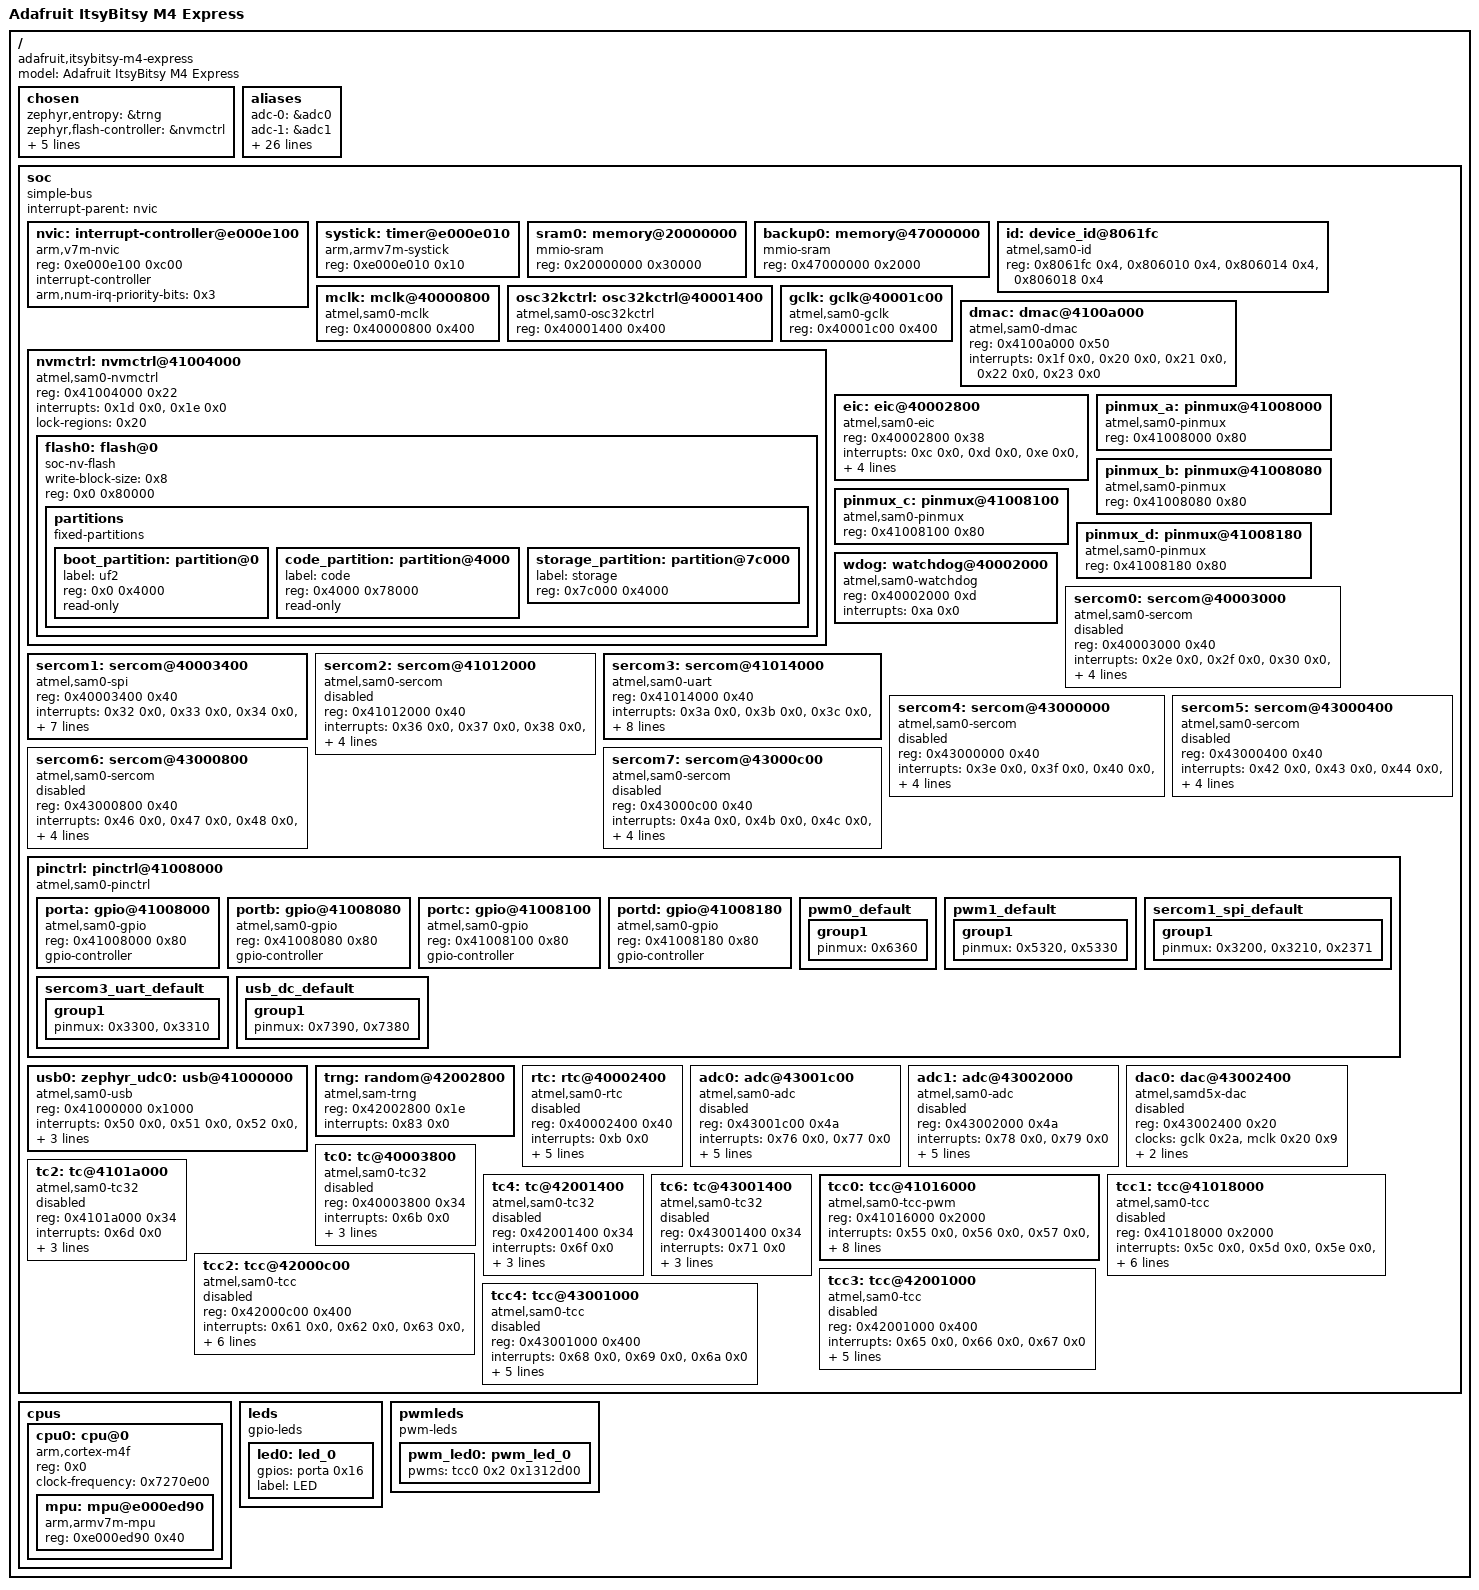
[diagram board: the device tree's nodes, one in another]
/dts-v1/;

/* node '/' defined in zephyr/dts/common/skeleton.dtsi:9 */
/ {
	#address-cells = < 0x1 >;                     /* in zephyr/dts/common/skeleton.dtsi:10 */
	#size-cells = < 0x1 >;                        /* in zephyr/dts/common/skeleton.dtsi:11 */
	model = "Adafruit ItsyBitsy M4 Express";      /* in zephyr/boards/adafruit/itsybitsy_m4_express/adafruit_itsybitsy_m4_express.dts:12 */
	compatible = "adafruit,itsybitsy-m4-express"; /* in zephyr/boards/adafruit/itsybitsy_m4_express/adafruit_itsybitsy_m4_express.dts:13 */

	/* node '/chosen' defined in zephyr/dts/common/skeleton.dtsi:13 */
	chosen {
		zephyr,entropy = &trng;                  /* in zephyr/dts/arm/atmel/samd5x.dtsi:51 */
		zephyr,flash-controller = &nvmctrl;      /* in zephyr/dts/arm/atmel/samd5x.dtsi:52 */
		zephyr,console = &sercom3;               /* in zephyr/boards/adafruit/itsybitsy_m4_express/adafruit_itsybitsy_m4_express.dts:16 */
		zephyr,shell-uart = &sercom3;            /* in zephyr/boards/adafruit/itsybitsy_m4_express/adafruit_itsybitsy_m4_express.dts:17 */
		zephyr,sram = &sram0;                    /* in zephyr/boards/adafruit/itsybitsy_m4_express/adafruit_itsybitsy_m4_express.dts:18 */
		zephyr,flash = &flash0;                  /* in zephyr/boards/adafruit/itsybitsy_m4_express/adafruit_itsybitsy_m4_express.dts:19 */
		zephyr,code-partition = &code_partition; /* in zephyr/boards/adafruit/itsybitsy_m4_express/adafruit_itsybitsy_m4_express.dts:20 */
	};

	/* node '/aliases' defined in zephyr/dts/common/skeleton.dtsi:15 */
	aliases {
		adc-0 = &adc0;        /* in zephyr/dts/arm/atmel/samd5x.dtsi:16 */
		adc-1 = &adc1;        /* in zephyr/dts/arm/atmel/samd5x.dtsi:17 */
		port-a = &porta;      /* in zephyr/dts/arm/atmel/samd5x.dtsi:19 */
		port-b = &portb;      /* in zephyr/dts/arm/atmel/samd5x.dtsi:20 */
		port-c = &portc;      /* in zephyr/dts/arm/atmel/samd5x.dtsi:21 */
		port-d = &portd;      /* in zephyr/dts/arm/atmel/samd5x.dtsi:22 */
		rtc = &rtc;           /* in zephyr/dts/arm/atmel/samd5x.dtsi:24 */
		sercom-0 = &sercom0;  /* in zephyr/dts/arm/atmel/samd5x.dtsi:26 */
		sercom-1 = &sercom1;  /* in zephyr/dts/arm/atmel/samd5x.dtsi:27 */
		sercom-2 = &sercom2;  /* in zephyr/dts/arm/atmel/samd5x.dtsi:28 */
		sercom-3 = &sercom3;  /* in zephyr/dts/arm/atmel/samd5x.dtsi:29 */
		sercom-4 = &sercom4;  /* in zephyr/dts/arm/atmel/samd5x.dtsi:30 */
		sercom-5 = &sercom5;  /* in zephyr/dts/arm/atmel/samd5x.dtsi:31 */
		sercom-6 = &sercom6;  /* in zephyr/dts/arm/atmel/samd5x.dtsi:32 */
		sercom-7 = &sercom7;  /* in zephyr/dts/arm/atmel/samd5x.dtsi:33 */
		tc-0 = &tc0;          /* in zephyr/dts/arm/atmel/samd5x.dtsi:35 */
		tc-2 = &tc2;          /* in zephyr/dts/arm/atmel/samd5x.dtsi:36 */
		tc-4 = &tc4;          /* in zephyr/dts/arm/atmel/samd5x.dtsi:37 */
		tc-6 = &tc6;          /* in zephyr/dts/arm/atmel/samd5x.dtsi:38 */
		tcc-0 = &tcc0;        /* in zephyr/dts/arm/atmel/samd5x.dtsi:40 */
		tcc-1 = &tcc1;        /* in zephyr/dts/arm/atmel/samd5x.dtsi:41 */
		tcc-2 = &tcc2;        /* in zephyr/dts/arm/atmel/samd5x.dtsi:42 */
		tcc-3 = &tcc3;        /* in zephyr/dts/arm/atmel/samd5x.dtsi:43 */
		tcc-4 = &tcc4;        /* in zephyr/dts/arm/atmel/samd5x.dtsi:44 */
		watchdog0 = &wdog;    /* in zephyr/dts/arm/atmel/samd5x.dtsi:46 */
		led0 = &led0;         /* in zephyr/boards/adafruit/itsybitsy_m4_express/adafruit_itsybitsy_m4_express.dts:25 */
		pwm-led0 = &pwm_led0; /* in zephyr/boards/adafruit/itsybitsy_m4_express/adafruit_itsybitsy_m4_express.dts:26 */
		pwm-0 = &tcc0;        /* in zephyr/boards/adafruit/itsybitsy_m4_express/adafruit_itsybitsy_m4_express.dts:27 */
	};

	/* node '/soc' defined in zephyr/dts/arm/armv7-m.dtsi:6 */
	soc {
		#address-cells = < 0x1 >;     /* in zephyr/dts/arm/armv7-m.dtsi:7 */
		#size-cells = < 0x1 >;        /* in zephyr/dts/arm/armv7-m.dtsi:8 */
		compatible = "simple-bus";    /* in zephyr/dts/arm/armv7-m.dtsi:9 */
		interrupt-parent = < &nvic >; /* in zephyr/dts/arm/armv7-m.dtsi:10 */
		ranges;                       /* in zephyr/dts/arm/armv7-m.dtsi:11 */

		/* node '/soc/interrupt-controller@e000e100' defined in zephyr/dts/arm/armv7-m.dtsi:13 */
		nvic: interrupt-controller@e000e100 {
			#address-cells = < 0x1 >;            /* in zephyr/dts/arm/armv7-m.dtsi:14 */
			compatible = "arm,v7m-nvic";         /* in zephyr/dts/arm/armv7-m.dtsi:15 */
			reg = < 0xe000e100 0xc00 >;          /* in zephyr/dts/arm/armv7-m.dtsi:16 */
			interrupt-controller;                /* in zephyr/dts/arm/armv7-m.dtsi:17 */
			#interrupt-cells = < 0x2 >;          /* in zephyr/dts/arm/armv7-m.dtsi:18 */
			arm,num-irq-priority-bits = < 0x3 >; /* in zephyr/dts/arm/atmel/samd5x.dtsi:522 */
			phandle = < 0x1 >;                   /* in zephyr/dts/arm/armv7-m.dtsi:10 */
		};

		/* node '/soc/timer@e000e010' defined in zephyr/dts/arm/armv7-m.dtsi:21 */
		systick: timer@e000e010 {
			compatible = "arm,armv7m-systick"; /* in zephyr/dts/arm/armv7-m.dtsi:22 */
			reg = < 0xe000e010 0x10 >;         /* in zephyr/dts/arm/armv7-m.dtsi:23 */
		};

		/* node '/soc/memory@20000000' defined in zephyr/dts/arm/atmel/samd5x.dtsi:76 */
		sram0: memory@20000000 {
			compatible = "mmio-sram";     /* in zephyr/dts/arm/atmel/samd5x.dtsi:77 */
			reg = < 0x20000000 0x30000 >; /* in zephyr/dts/arm/atmel/samd5xx19.dtsi:19 */
		};

		/* node '/soc/memory@47000000' defined in zephyr/dts/arm/atmel/samd5x.dtsi:81 */
		backup0: memory@47000000 {
			compatible = "mmio-sram";    /* in zephyr/dts/arm/atmel/samd5x.dtsi:82 */
			reg = < 0x47000000 0x2000 >; /* in zephyr/dts/arm/atmel/samd5x.dtsi:83 */
		};

		/* node '/soc/device_id@8061fc' defined in zephyr/dts/arm/atmel/samd5x.dtsi:86 */
		id: device_id@8061fc {
			compatible = "atmel,sam0-id"; /* in zephyr/dts/arm/atmel/samd5x.dtsi:87 */
			reg = < 0x8061fc 0x4 >,
			      < 0x806010 0x4 >,
			      < 0x806014 0x4 >,
			      < 0x806018 0x4 >;       /* in zephyr/dts/arm/atmel/samd5x.dtsi:88 */
		};

		/* node '/soc/mclk@40000800' defined in zephyr/dts/arm/atmel/samd5x.dtsi:94 */
		mclk: mclk@40000800 {
			compatible = "atmel,sam0-mclk"; /* in zephyr/dts/arm/atmel/samd5x.dtsi:95 */
			reg = < 0x40000800 0x400 >;     /* in zephyr/dts/arm/atmel/samd5x.dtsi:96 */
			#clock-cells = < 0x2 >;         /* in zephyr/dts/arm/atmel/samd5x.dtsi:98 */
			phandle = < 0x3 >;              /* in zephyr/dts/arm/atmel/samd5x.dtsi:181 */
		};

		/* node '/soc/osc32kctrl@40001400' defined in zephyr/dts/arm/atmel/samd5x.dtsi:101 */
		osc32kctrl: osc32kctrl@40001400 {
			compatible = "atmel,sam0-osc32kctrl";  /* in zephyr/dts/arm/atmel/samd5x.dtsi:102 */
			reg = < 0x40001400 0x400 >;            /* in zephyr/dts/arm/atmel/samd5x.dtsi:103 */
			#clock-cells = < 0x0 >;                /* in zephyr/dts/arm/atmel/samd5x.dtsi:104 */
			#atmel,assigned-clock-cells = < 0x1 >; /* in zephyr/dts/arm/atmel/samd5x.dtsi:105 */
			phandle = < 0x7 >;                     /* in zephyr/dts/arm/atmel/samd5x.dtsi:332 */
		};

		/* node '/soc/gclk@40001c00' defined in zephyr/dts/arm/atmel/samd5x.dtsi:108 */
		gclk: gclk@40001c00 {
			compatible = "atmel,sam0-gclk";        /* in zephyr/dts/arm/atmel/samd5x.dtsi:109 */
			reg = < 0x40001c00 0x400 >;            /* in zephyr/dts/arm/atmel/samd5x.dtsi:110 */
			#clock-cells = < 0x1 >;                /* in zephyr/dts/arm/atmel/samd5x.dtsi:112 */
			#atmel,assigned-clock-cells = < 0x1 >; /* in zephyr/dts/arm/atmel/samd5x.dtsi:113 */
			phandle = < 0x2 >;                     /* in zephyr/dts/arm/atmel/samd5x.dtsi:181 */
		};

		/* node '/soc/nvmctrl@41004000' defined in zephyr/dts/arm/atmel/samd5x.dtsi:116 */
		nvmctrl: nvmctrl@41004000 {
			compatible = "atmel,sam0-nvmctrl"; /* in zephyr/dts/arm/atmel/samd5x.dtsi:117 */
			reg = < 0x41004000 0x22 >;         /* in zephyr/dts/arm/atmel/samd5x.dtsi:118 */
			interrupts = < 0x1d 0x0 >,
			             < 0x1e 0x0 >;         /* in zephyr/dts/arm/atmel/samd5x.dtsi:119 */
			#address-cells = < 0x1 >;          /* in zephyr/dts/arm/atmel/samd5x.dtsi:121 */
			#size-cells = < 0x1 >;             /* in zephyr/dts/arm/atmel/samd5x.dtsi:122 */
			lock-regions = < 0x20 >;           /* in zephyr/dts/arm/atmel/samd5x.dtsi:124 */

			/* node '/soc/nvmctrl@41004000/flash@0' defined in zephyr/dts/arm/atmel/samd5x.dtsi:126 */
			flash0: flash@0 {
				compatible = "soc-nv-flash"; /* in zephyr/dts/arm/atmel/samd5x.dtsi:127 */
				write-block-size = < 0x8 >;  /* in zephyr/dts/arm/atmel/samd5x.dtsi:129 */
				reg = < 0x0 0x80000 >;       /* in zephyr/dts/arm/atmel/samd5xx19.dtsi:14 */

				/* node '/soc/nvmctrl@41004000/flash@0/partitions' defined in zephyr/boards/adafruit/itsybitsy_m4_express/adafruit_itsybitsy_m4_express.dts:98 */
				partitions {
					compatible = "fixed-partitions"; /* in zephyr/boards/adafruit/itsybitsy_m4_express/adafruit_itsybitsy_m4_express.dts:99 */
					#address-cells = < 0x1 >;        /* in zephyr/boards/adafruit/itsybitsy_m4_express/adafruit_itsybitsy_m4_express.dts:100 */
					#size-cells = < 0x1 >;           /* in zephyr/boards/adafruit/itsybitsy_m4_express/adafruit_itsybitsy_m4_express.dts:101 */

					/* node '/soc/nvmctrl@41004000/flash@0/partitions/partition@0' defined in zephyr/boards/adafruit/itsybitsy_m4_express/adafruit_itsybitsy_m4_express.dts:103 */
					boot_partition: partition@0 {
						label = "uf2";        /* in zephyr/boards/adafruit/itsybitsy_m4_express/adafruit_itsybitsy_m4_express.dts:104 */
						reg = < 0x0 0x4000 >; /* in zephyr/boards/adafruit/itsybitsy_m4_express/adafruit_itsybitsy_m4_express.dts:105 */
						read-only;            /* in zephyr/boards/adafruit/itsybitsy_m4_express/adafruit_itsybitsy_m4_express.dts:106 */
					};

					/* node '/soc/nvmctrl@41004000/flash@0/partitions/partition@4000' defined in zephyr/boards/adafruit/itsybitsy_m4_express/adafruit_itsybitsy_m4_express.dts:109 */
					code_partition: partition@4000 {
						label = "code";           /* in zephyr/boards/adafruit/itsybitsy_m4_express/adafruit_itsybitsy_m4_express.dts:110 */
						reg = < 0x4000 0x78000 >; /* in zephyr/boards/adafruit/itsybitsy_m4_express/adafruit_itsybitsy_m4_express.dts:111 */
						read-only;                /* in zephyr/boards/adafruit/itsybitsy_m4_express/adafruit_itsybitsy_m4_express.dts:112 */
					};

					/* node '/soc/nvmctrl@41004000/flash@0/partitions/partition@7c000' defined in zephyr/boards/adafruit/itsybitsy_m4_express/adafruit_itsybitsy_m4_express.dts:120 */
					storage_partition: partition@7c000 {
						label = "storage";        /* in zephyr/boards/adafruit/itsybitsy_m4_express/adafruit_itsybitsy_m4_express.dts:121 */
						reg = < 0x7c000 0x4000 >; /* in zephyr/boards/adafruit/itsybitsy_m4_express/adafruit_itsybitsy_m4_express.dts:122 */
					};
				};
			};
		};

		/* node '/soc/dmac@4100a000' defined in zephyr/dts/arm/atmel/samd5x.dtsi:133 */
		dmac: dmac@4100a000 {
			compatible = "atmel,sam0-dmac"; /* in zephyr/dts/arm/atmel/samd5x.dtsi:134 */
			reg = < 0x4100a000 0x50 >;      /* in zephyr/dts/arm/atmel/samd5x.dtsi:135 */
			interrupts = < 0x1f 0x0 >,
			             < 0x20 0x0 >,
			             < 0x21 0x0 >,
			             < 0x22 0x0 >,
			             < 0x23 0x0 >;      /* in zephyr/dts/arm/atmel/samd5x.dtsi:136 */
			#dma-cells = < 0x2 >;           /* in zephyr/dts/arm/atmel/samd5x.dtsi:139 */
			status = "okay";                /* in zephyr/boards/adafruit/itsybitsy_m4_express/adafruit_itsybitsy_m4_express.dts:94 */
		};

		/* node '/soc/eic@40002800' defined in zephyr/dts/arm/atmel/samd5x.dtsi:142 */
		eic: eic@40002800 {
			compatible = "atmel,sam0-eic"; /* in zephyr/dts/arm/atmel/samd5x.dtsi:143 */
			reg = < 0x40002800 0x38 >;     /* in zephyr/dts/arm/atmel/samd5x.dtsi:144 */
			interrupts = < 0xc 0x0 >,
			             < 0xd 0x0 >,
			             < 0xe 0x0 >,
			             < 0xf 0x0 >,
			             < 0x10 0x0 >,
			             < 0x11 0x0 >,
			             < 0x12 0x0 >,
			             < 0x13 0x0 >,
			             < 0x14 0x0 >,
			             < 0x15 0x0 >,
			             < 0x16 0x0 >,
			             < 0x17 0x0 >,
			             < 0x18 0x0 >,
			             < 0x19 0x0 >,
			             < 0x1a 0x0 >,
			             < 0x1b 0x0 >;     /* in zephyr/dts/arm/atmel/samd5x.dtsi:145 */
		};

		/* node '/soc/pinmux@41008000' defined in zephyr/dts/arm/atmel/samd5x.dtsi:151 */
		pinmux_a: pinmux@41008000 {
			compatible = "atmel,sam0-pinmux"; /* in zephyr/dts/arm/atmel/samd5x.dtsi:152 */
			reg = < 0x41008000 0x80 >;        /* in zephyr/dts/arm/atmel/samd5x.dtsi:153 */
		};

		/* node '/soc/pinmux@41008080' defined in zephyr/dts/arm/atmel/samd5x.dtsi:156 */
		pinmux_b: pinmux@41008080 {
			compatible = "atmel,sam0-pinmux"; /* in zephyr/dts/arm/atmel/samd5x.dtsi:157 */
			reg = < 0x41008080 0x80 >;        /* in zephyr/dts/arm/atmel/samd5x.dtsi:158 */
		};

		/* node '/soc/pinmux@41008100' defined in zephyr/dts/arm/atmel/samd5x.dtsi:161 */
		pinmux_c: pinmux@41008100 {
			compatible = "atmel,sam0-pinmux"; /* in zephyr/dts/arm/atmel/samd5x.dtsi:162 */
			reg = < 0x41008100 0x80 >;        /* in zephyr/dts/arm/atmel/samd5x.dtsi:163 */
		};

		/* node '/soc/pinmux@41008180' defined in zephyr/dts/arm/atmel/samd5x.dtsi:166 */
		pinmux_d: pinmux@41008180 {
			compatible = "atmel,sam0-pinmux"; /* in zephyr/dts/arm/atmel/samd5x.dtsi:167 */
			reg = < 0x41008180 0x80 >;        /* in zephyr/dts/arm/atmel/samd5x.dtsi:168 */
		};

		/* node '/soc/watchdog@40002000' defined in zephyr/dts/arm/atmel/samd5x.dtsi:171 */
		wdog: watchdog@40002000 {
			compatible = "atmel,sam0-watchdog"; /* in zephyr/dts/arm/atmel/samd5x.dtsi:172 */
			reg = < 0x40002000 0xd >;           /* in zephyr/dts/arm/atmel/samd5x.dtsi:173 */
			interrupts = < 0xa 0x0 >;           /* in zephyr/dts/arm/atmel/samd5x.dtsi:174 */
		};

		/* node '/soc/sercom@40003000' defined in zephyr/dts/arm/atmel/samd5x.dtsi:177 */
		sercom0: sercom@40003000 {
			compatible = "atmel,sam0-sercom";      /* in zephyr/dts/arm/atmel/samd5x.dtsi:178 */
			reg = < 0x40003000 0x40 >;             /* in zephyr/dts/arm/atmel/samd5x.dtsi:179 */
			interrupts = < 0x2e 0x0 >,
			             < 0x2f 0x0 >,
			             < 0x30 0x0 >,
			             < 0x31 0x0 >;             /* in zephyr/dts/arm/atmel/samd5x.dtsi:180 */
			clocks = < &gclk 0x7 >,
			         < &mclk 0x14 0xc >;           /* in zephyr/dts/arm/atmel/samd5x.dtsi:181 */
			clock-names = "GCLK",
			              "MCLK";                  /* in zephyr/dts/arm/atmel/samd5x.dtsi:182 */
			atmel,assigned-clocks = < &gclk 0x0 >; /* in zephyr/dts/arm/atmel/samd5x.dtsi:183 */
			atmel,assigned-clock-names = "GCLK";   /* in zephyr/dts/arm/atmel/samd5x.dtsi:184 */
			status = "disabled";                   /* in zephyr/dts/arm/atmel/samd5x.dtsi:185 */
		};

		/* node '/soc/sercom@40003400' defined in zephyr/dts/arm/atmel/samd5x.dtsi:188 */
		sercom1: sercom@40003400 {
			reg = < 0x40003400 0x40 >;             /* in zephyr/dts/arm/atmel/samd5x.dtsi:190 */
			interrupts = < 0x32 0x0 >,
			             < 0x33 0x0 >,
			             < 0x34 0x0 >,
			             < 0x35 0x0 >;             /* in zephyr/dts/arm/atmel/samd5x.dtsi:191 */
			clocks = < &gclk 0x8 >,
			         < &mclk 0x14 0xd >;           /* in zephyr/dts/arm/atmel/samd5x.dtsi:192 */
			clock-names = "GCLK",
			              "MCLK";                  /* in zephyr/dts/arm/atmel/samd5x.dtsi:193 */
			atmel,assigned-clocks = < &gclk 0x0 >; /* in zephyr/dts/arm/atmel/samd5x.dtsi:194 */
			atmel,assigned-clock-names = "GCLK";   /* in zephyr/dts/arm/atmel/samd5x.dtsi:195 */
			status = "okay";                       /* in zephyr/boards/adafruit/itsybitsy_m4_express/adafruit_itsybitsy_m4_express.dts:64 */
			compatible = "atmel,sam0-spi";         /* in zephyr/boards/adafruit/itsybitsy_m4_express/adafruit_itsybitsy_m4_express.dts:65 */
			dipo = < 0x3 >;                        /* in zephyr/boards/adafruit/itsybitsy_m4_express/adafruit_itsybitsy_m4_express.dts:66 */
			dopo = < 0x0 >;                        /* in zephyr/boards/adafruit/itsybitsy_m4_express/adafruit_itsybitsy_m4_express.dts:67 */
			#address-cells = < 0x1 >;              /* in zephyr/boards/adafruit/itsybitsy_m4_express/adafruit_itsybitsy_m4_express.dts:69 */
			#size-cells = < 0x0 >;                 /* in zephyr/boards/adafruit/itsybitsy_m4_express/adafruit_itsybitsy_m4_express.dts:70 */
			pinctrl-0 = < &sercom1_spi_default >;  /* in zephyr/boards/adafruit/itsybitsy_m4_express/adafruit_itsybitsy_m4_express.dts:72 */
			pinctrl-names = "default";             /* in zephyr/boards/adafruit/itsybitsy_m4_express/adafruit_itsybitsy_m4_express.dts:73 */
		};

		/* node '/soc/sercom@41012000' defined in zephyr/dts/arm/atmel/samd5x.dtsi:199 */
		sercom2: sercom@41012000 {
			compatible = "atmel,sam0-sercom";      /* in zephyr/dts/arm/atmel/samd5x.dtsi:200 */
			reg = < 0x41012000 0x40 >;             /* in zephyr/dts/arm/atmel/samd5x.dtsi:201 */
			interrupts = < 0x36 0x0 >,
			             < 0x37 0x0 >,
			             < 0x38 0x0 >,
			             < 0x39 0x0 >;             /* in zephyr/dts/arm/atmel/samd5x.dtsi:202 */
			clocks = < &gclk 0x17 >,
			         < &mclk 0x18 0x9 >;           /* in zephyr/dts/arm/atmel/samd5x.dtsi:203 */
			clock-names = "GCLK",
			              "MCLK";                  /* in zephyr/dts/arm/atmel/samd5x.dtsi:204 */
			atmel,assigned-clocks = < &gclk 0x0 >; /* in zephyr/dts/arm/atmel/samd5x.dtsi:205 */
			atmel,assigned-clock-names = "GCLK";   /* in zephyr/dts/arm/atmel/samd5x.dtsi:206 */
			status = "disabled";                   /* in zephyr/dts/arm/atmel/samd5x.dtsi:207 */
		};

		/* node '/soc/sercom@41014000' defined in zephyr/dts/arm/atmel/samd5x.dtsi:210 */
		sercom3: sercom@41014000 {
			reg = < 0x41014000 0x40 >;             /* in zephyr/dts/arm/atmel/samd5x.dtsi:212 */
			interrupts = < 0x3a 0x0 >,
			             < 0x3b 0x0 >,
			             < 0x3c 0x0 >,
			             < 0x3d 0x0 >;             /* in zephyr/dts/arm/atmel/samd5x.dtsi:213 */
			clocks = < &gclk 0x18 >,
			         < &mclk 0x18 0xa >;           /* in zephyr/dts/arm/atmel/samd5x.dtsi:214 */
			clock-names = "GCLK",
			              "MCLK";                  /* in zephyr/dts/arm/atmel/samd5x.dtsi:215 */
			atmel,assigned-clocks = < &gclk 0x0 >; /* in zephyr/dts/arm/atmel/samd5x.dtsi:216 */
			atmel,assigned-clock-names = "GCLK";   /* in zephyr/dts/arm/atmel/samd5x.dtsi:217 */
			status = "okay";                       /* in zephyr/boards/adafruit/itsybitsy_m4_express/adafruit_itsybitsy_m4_express.dts:53 */
			compatible = "atmel,sam0-uart";        /* in zephyr/boards/adafruit/itsybitsy_m4_express/adafruit_itsybitsy_m4_express.dts:54 */
			current-speed = < 0x1c200 >;           /* in zephyr/boards/adafruit/itsybitsy_m4_express/adafruit_itsybitsy_m4_express.dts:55 */
			rxpo = < 0x1 >;                        /* in zephyr/boards/adafruit/itsybitsy_m4_express/adafruit_itsybitsy_m4_express.dts:56 */
			txpo = < 0x0 >;                        /* in zephyr/boards/adafruit/itsybitsy_m4_express/adafruit_itsybitsy_m4_express.dts:57 */
			pinctrl-0 = < &sercom3_uart_default >; /* in zephyr/boards/adafruit/itsybitsy_m4_express/adafruit_itsybitsy_m4_express.dts:59 */
			pinctrl-names = "default";             /* in zephyr/boards/adafruit/itsybitsy_m4_express/adafruit_itsybitsy_m4_express.dts:60 */
		};

		/* node '/soc/sercom@43000000' defined in zephyr/dts/arm/atmel/samd5x.dtsi:221 */
		sercom4: sercom@43000000 {
			compatible = "atmel,sam0-sercom";      /* in zephyr/dts/arm/atmel/samd5x.dtsi:222 */
			reg = < 0x43000000 0x40 >;             /* in zephyr/dts/arm/atmel/samd5x.dtsi:223 */
			interrupts = < 0x3e 0x0 >,
			             < 0x3f 0x0 >,
			             < 0x40 0x0 >,
			             < 0x41 0x0 >;             /* in zephyr/dts/arm/atmel/samd5x.dtsi:224 */
			clocks = < &gclk 0x22 >,
			         < &mclk 0x20 0x0 >;           /* in zephyr/dts/arm/atmel/samd5x.dtsi:225 */
			clock-names = "GCLK",
			              "MCLK";                  /* in zephyr/dts/arm/atmel/samd5x.dtsi:226 */
			atmel,assigned-clocks = < &gclk 0x0 >; /* in zephyr/dts/arm/atmel/samd5x.dtsi:227 */
			atmel,assigned-clock-names = "GCLK";   /* in zephyr/dts/arm/atmel/samd5x.dtsi:228 */
			status = "disabled";                   /* in zephyr/dts/arm/atmel/samd5x.dtsi:229 */
		};

		/* node '/soc/sercom@43000400' defined in zephyr/dts/arm/atmel/samd5x.dtsi:232 */
		sercom5: sercom@43000400 {
			compatible = "atmel,sam0-sercom";      /* in zephyr/dts/arm/atmel/samd5x.dtsi:233 */
			reg = < 0x43000400 0x40 >;             /* in zephyr/dts/arm/atmel/samd5x.dtsi:234 */
			interrupts = < 0x42 0x0 >,
			             < 0x43 0x0 >,
			             < 0x44 0x0 >,
			             < 0x45 0x0 >;             /* in zephyr/dts/arm/atmel/samd5x.dtsi:235 */
			clocks = < &gclk 0x23 >,
			         < &mclk 0x20 0x1 >;           /* in zephyr/dts/arm/atmel/samd5x.dtsi:236 */
			clock-names = "GCLK",
			              "MCLK";                  /* in zephyr/dts/arm/atmel/samd5x.dtsi:237 */
			atmel,assigned-clocks = < &gclk 0x0 >; /* in zephyr/dts/arm/atmel/samd5x.dtsi:238 */
			atmel,assigned-clock-names = "GCLK";   /* in zephyr/dts/arm/atmel/samd5x.dtsi:239 */
			status = "disabled";                   /* in zephyr/dts/arm/atmel/samd5x.dtsi:240 */
		};

		/* node '/soc/sercom@43000800' defined in zephyr/dts/arm/atmel/samd5x.dtsi:243 */
		sercom6: sercom@43000800 {
			compatible = "atmel,sam0-sercom";      /* in zephyr/dts/arm/atmel/samd5x.dtsi:244 */
			reg = < 0x43000800 0x40 >;             /* in zephyr/dts/arm/atmel/samd5x.dtsi:245 */
			interrupts = < 0x46 0x0 >,
			             < 0x47 0x0 >,
			             < 0x48 0x0 >,
			             < 0x49 0x0 >;             /* in zephyr/dts/arm/atmel/samd5x.dtsi:246 */
			clocks = < &gclk 0x24 >,
			         < &mclk 0x20 0x2 >;           /* in zephyr/dts/arm/atmel/samd5x.dtsi:247 */
			clock-names = "GCLK",
			              "MCLK";                  /* in zephyr/dts/arm/atmel/samd5x.dtsi:248 */
			atmel,assigned-clocks = < &gclk 0x0 >; /* in zephyr/dts/arm/atmel/samd5x.dtsi:249 */
			atmel,assigned-clock-names = "GCLK";   /* in zephyr/dts/arm/atmel/samd5x.dtsi:250 */
			status = "disabled";                   /* in zephyr/dts/arm/atmel/samd5x.dtsi:251 */
		};

		/* node '/soc/sercom@43000c00' defined in zephyr/dts/arm/atmel/samd5x.dtsi:254 */
		sercom7: sercom@43000c00 {
			compatible = "atmel,sam0-sercom";      /* in zephyr/dts/arm/atmel/samd5x.dtsi:255 */
			reg = < 0x43000c00 0x40 >;             /* in zephyr/dts/arm/atmel/samd5x.dtsi:256 */
			interrupts = < 0x4a 0x0 >,
			             < 0x4b 0x0 >,
			             < 0x4c 0x0 >,
			             < 0x4d 0x0 >;             /* in zephyr/dts/arm/atmel/samd5x.dtsi:257 */
			clocks = < &gclk 0x25 >,
			         < &mclk 0x20 0x3 >;           /* in zephyr/dts/arm/atmel/samd5x.dtsi:258 */
			clock-names = "GCLK",
			              "MCLK";                  /* in zephyr/dts/arm/atmel/samd5x.dtsi:259 */
			atmel,assigned-clocks = < &gclk 0x0 >; /* in zephyr/dts/arm/atmel/samd5x.dtsi:260 */
			atmel,assigned-clock-names = "GCLK";   /* in zephyr/dts/arm/atmel/samd5x.dtsi:261 */
			status = "disabled";                   /* in zephyr/dts/arm/atmel/samd5x.dtsi:262 */
		};

		/* node '/soc/pinctrl@41008000' defined in zephyr/dts/arm/atmel/samd5x.dtsi:265 */
		pinctrl: pinctrl@41008000 {
			compatible = "atmel,sam0-pinctrl";        /* in zephyr/dts/arm/atmel/samd5x.dtsi:266 */
			ranges = < 0x41008000 0x41008000 0x200 >; /* in zephyr/dts/arm/atmel/samd5x.dtsi:267 */
			#address-cells = < 0x1 >;                 /* in zephyr/dts/arm/atmel/samd5x.dtsi:269 */
			#size-cells = < 0x1 >;                    /* in zephyr/dts/arm/atmel/samd5x.dtsi:270 */

			/* node '/soc/pinctrl@41008000/gpio@41008000' defined in zephyr/dts/arm/atmel/samd5x.dtsi:272 */
			porta: gpio@41008000 {
				compatible = "atmel,sam0-gpio"; /* in zephyr/dts/arm/atmel/samd5x.dtsi:273 */
				reg = < 0x41008000 0x80 >;      /* in zephyr/dts/arm/atmel/samd5x.dtsi:274 */
				#atmel,pin-cells = < 0x2 >;     /* in zephyr/dts/arm/atmel/samd5x.dtsi:276 */
				#gpio-cells = < 0x2 >;          /* in zephyr/dts/arm/atmel/samd5x.dtsi:277 */
				gpio-controller;                /* in zephyr/dts/arm/atmel/samd5x.dtsi:279 */
				phandle = < 0x9 >;              /* in zephyr/boards/adafruit/itsybitsy_m4_express/adafruit_itsybitsy_m4_express.dts:34 */
			};

			/* node '/soc/pinctrl@41008000/gpio@41008080' defined in zephyr/dts/arm/atmel/samd5x.dtsi:282 */
			portb: gpio@41008080 {
				compatible = "atmel,sam0-gpio"; /* in zephyr/dts/arm/atmel/samd5x.dtsi:283 */
				reg = < 0x41008080 0x80 >;      /* in zephyr/dts/arm/atmel/samd5x.dtsi:284 */
				#atmel,pin-cells = < 0x2 >;     /* in zephyr/dts/arm/atmel/samd5x.dtsi:286 */
				#gpio-cells = < 0x2 >;          /* in zephyr/dts/arm/atmel/samd5x.dtsi:287 */
				gpio-controller;                /* in zephyr/dts/arm/atmel/samd5x.dtsi:289 */
			};

			/* node '/soc/pinctrl@41008000/gpio@41008100' defined in zephyr/dts/arm/atmel/samd5x.dtsi:292 */
			portc: gpio@41008100 {
				compatible = "atmel,sam0-gpio"; /* in zephyr/dts/arm/atmel/samd5x.dtsi:293 */
				reg = < 0x41008100 0x80 >;      /* in zephyr/dts/arm/atmel/samd5x.dtsi:294 */
				#atmel,pin-cells = < 0x2 >;     /* in zephyr/dts/arm/atmel/samd5x.dtsi:296 */
				#gpio-cells = < 0x2 >;          /* in zephyr/dts/arm/atmel/samd5x.dtsi:297 */
				gpio-controller;                /* in zephyr/dts/arm/atmel/samd5x.dtsi:299 */
			};

			/* node '/soc/pinctrl@41008000/gpio@41008180' defined in zephyr/dts/arm/atmel/samd5x.dtsi:302 */
			portd: gpio@41008180 {
				compatible = "atmel,sam0-gpio"; /* in zephyr/dts/arm/atmel/samd5x.dtsi:303 */
				reg = < 0x41008180 0x80 >;      /* in zephyr/dts/arm/atmel/samd5x.dtsi:304 */
				#atmel,pin-cells = < 0x2 >;     /* in zephyr/dts/arm/atmel/samd5x.dtsi:306 */
				#gpio-cells = < 0x2 >;          /* in zephyr/dts/arm/atmel/samd5x.dtsi:307 */
				gpio-controller;                /* in zephyr/dts/arm/atmel/samd5x.dtsi:309 */
			};

			/* node '/soc/pinctrl@41008000/pwm0_default' defined in zephyr/boards/adafruit/itsybitsy_m4_express/adafruit_itsybitsy_m4_express-pinctrl.dtsi:9 */
			pwm0_default: pwm0_default {
				phandle = < 0x8 >; /* in zephyr/boards/adafruit/itsybitsy_m4_express/adafruit_itsybitsy_m4_express.dts:82 */

				/* node '/soc/pinctrl@41008000/pwm0_default/group1' defined in zephyr/boards/adafruit/itsybitsy_m4_express/adafruit_itsybitsy_m4_express-pinctrl.dtsi:10 */
				group1 {
					pinmux = < 0x6360 >; /* in zephyr/boards/adafruit/itsybitsy_m4_express/adafruit_itsybitsy_m4_express-pinctrl.dtsi:11 */
				};
			};

			/* node '/soc/pinctrl@41008000/pwm1_default' defined in zephyr/boards/adafruit/itsybitsy_m4_express/adafruit_itsybitsy_m4_express-pinctrl.dtsi:15 */
			pwm1_default: pwm1_default {

				/* node '/soc/pinctrl@41008000/pwm1_default/group1' defined in zephyr/boards/adafruit/itsybitsy_m4_express/adafruit_itsybitsy_m4_express-pinctrl.dtsi:16 */
				group1 {
					pinmux = < 0x5320 >,
					         < 0x5330 >; /* in zephyr/boards/adafruit/itsybitsy_m4_express/adafruit_itsybitsy_m4_express-pinctrl.dtsi:17 */
				};
			};

			/* node '/soc/pinctrl@41008000/sercom1_spi_default' defined in zephyr/boards/adafruit/itsybitsy_m4_express/adafruit_itsybitsy_m4_express-pinctrl.dtsi:22 */
			sercom1_spi_default: sercom1_spi_default {
				phandle = < 0x4 >; /* in zephyr/boards/adafruit/itsybitsy_m4_express/adafruit_itsybitsy_m4_express.dts:72 */

				/* node '/soc/pinctrl@41008000/sercom1_spi_default/group1' defined in zephyr/boards/adafruit/itsybitsy_m4_express/adafruit_itsybitsy_m4_express-pinctrl.dtsi:23 */
				group1 {
					pinmux = < 0x3200 >,
					         < 0x3210 >,
					         < 0x2371 >; /* in zephyr/boards/adafruit/itsybitsy_m4_express/adafruit_itsybitsy_m4_express-pinctrl.dtsi:24 */
				};
			};

			/* node '/soc/pinctrl@41008000/sercom3_uart_default' defined in zephyr/boards/adafruit/itsybitsy_m4_express/adafruit_itsybitsy_m4_express-pinctrl.dtsi:30 */
			sercom3_uart_default: sercom3_uart_default {
				phandle = < 0x5 >; /* in zephyr/boards/adafruit/itsybitsy_m4_express/adafruit_itsybitsy_m4_express.dts:59 */

				/* node '/soc/pinctrl@41008000/sercom3_uart_default/group1' defined in zephyr/boards/adafruit/itsybitsy_m4_express/adafruit_itsybitsy_m4_express-pinctrl.dtsi:31 */
				group1 {
					pinmux = < 0x3300 >,
					         < 0x3310 >; /* in zephyr/boards/adafruit/itsybitsy_m4_express/adafruit_itsybitsy_m4_express-pinctrl.dtsi:32 */
				};
			};

			/* node '/soc/pinctrl@41008000/usb_dc_default' defined in zephyr/boards/adafruit/itsybitsy_m4_express/adafruit_itsybitsy_m4_express-pinctrl.dtsi:37 */
			usb_dc_default: usb_dc_default {
				phandle = < 0x6 >; /* in zephyr/boards/adafruit/itsybitsy_m4_express/adafruit_itsybitsy_m4_express.dts:89 */

				/* node '/soc/pinctrl@41008000/usb_dc_default/group1' defined in zephyr/boards/adafruit/itsybitsy_m4_express/adafruit_itsybitsy_m4_express-pinctrl.dtsi:38 */
				group1 {
					pinmux = < 0x7390 >,
					         < 0x7380 >; /* in zephyr/boards/adafruit/itsybitsy_m4_express/adafruit_itsybitsy_m4_express-pinctrl.dtsi:39 */
				};
			};
		};

		/* node '/soc/usb@41000000' defined in zephyr/dts/arm/atmel/samd5x.dtsi:313 */
		usb0: zephyr_udc0: usb@41000000 {
			compatible = "atmel,sam0-usb";   /* in zephyr/dts/arm/atmel/samd5x.dtsi:314 */
			reg = < 0x41000000 0x1000 >;     /* in zephyr/dts/arm/atmel/samd5x.dtsi:315 */
			interrupts = < 0x50 0x0 >,
			             < 0x51 0x0 >,
			             < 0x52 0x0 >,
			             < 0x53 0x0 >;       /* in zephyr/dts/arm/atmel/samd5x.dtsi:316 */
			num-bidir-endpoints = < 0x8 >;   /* in zephyr/dts/arm/atmel/samd5x.dtsi:319 */
			status = "okay";                 /* in zephyr/boards/adafruit/itsybitsy_m4_express/adafruit_itsybitsy_m4_express.dts:87 */
			pinctrl-0 = < &usb_dc_default >; /* in zephyr/boards/adafruit/itsybitsy_m4_express/adafruit_itsybitsy_m4_express.dts:89 */
			pinctrl-names = "default";       /* in zephyr/boards/adafruit/itsybitsy_m4_express/adafruit_itsybitsy_m4_express.dts:90 */
		};

		/* node '/soc/random@42002800' defined in zephyr/dts/arm/atmel/samd5x.dtsi:322 */
		trng: random@42002800 {
			compatible = "atmel,sam-trng"; /* in zephyr/dts/arm/atmel/samd5x.dtsi:323 */
			reg = < 0x42002800 0x1e >;     /* in zephyr/dts/arm/atmel/samd5x.dtsi:324 */
			interrupts = < 0x83 0x0 >;     /* in zephyr/dts/arm/atmel/samd5x.dtsi:325 */
		};

		/* node '/soc/rtc@40002400' defined in zephyr/dts/arm/atmel/samd5x.dtsi:328 */
		rtc: rtc@40002400 {
			compatible = "atmel,sam0-rtc";               /* in zephyr/dts/arm/atmel/samd5x.dtsi:329 */
			reg = < 0x40002400 0x40 >;                   /* in zephyr/dts/arm/atmel/samd5x.dtsi:330 */
			interrupts = < 0xb 0x0 >;                    /* in zephyr/dts/arm/atmel/samd5x.dtsi:331 */
			clocks = < &osc32kctrl >,
			         < &mclk 0x14 0x9 >;                 /* in zephyr/dts/arm/atmel/samd5x.dtsi:332 */
			clock-names = "OSC32KCTRL",
			              "MCLK";                        /* in zephyr/dts/arm/atmel/samd5x.dtsi:333 */
			atmel,assigned-clocks = < &osc32kctrl 0x0 >; /* in zephyr/dts/arm/atmel/samd5x.dtsi:334 */
			atmel,assigned-clock-names = "OSC32KCTRL";   /* in zephyr/dts/arm/atmel/samd5x.dtsi:335 */
			status = "disabled";                         /* in zephyr/dts/arm/atmel/samd5x.dtsi:336 */
			alarms-count = < 0x2 >;                      /* in zephyr/dts/arm/atmel/samd5x.dtsi:338 */
			cal-constant = < 0x100000 >;                 /* in zephyr/dts/arm/atmel/samd5x.dtsi:339 */
		};

		/* node '/soc/adc@43001c00' defined in zephyr/dts/arm/atmel/samd5x.dtsi:342 */
		adc0: adc@43001c00 {
			compatible = "atmel,sam0-adc";         /* in zephyr/dts/arm/atmel/samd5x.dtsi:343 */
			reg = < 0x43001c00 0x4a >;             /* in zephyr/dts/arm/atmel/samd5x.dtsi:344 */
			interrupts = < 0x76 0x0 >,
			             < 0x77 0x0 >;             /* in zephyr/dts/arm/atmel/samd5x.dtsi:345 */
			interrupt-names = "overrun",
			                  "resrdy";            /* in zephyr/dts/arm/atmel/samd5x.dtsi:346 */
			clocks = < &gclk 0x28 >,
			         < &mclk 0x20 0x7 >;           /* in zephyr/dts/arm/atmel/samd5x.dtsi:347 */
			clock-names = "GCLK",
			              "MCLK";                  /* in zephyr/dts/arm/atmel/samd5x.dtsi:348 */
			atmel,assigned-clocks = < &gclk 0x2 >; /* in zephyr/dts/arm/atmel/samd5x.dtsi:356 */
			atmel,assigned-clock-names = "GCLK";   /* in zephyr/dts/arm/atmel/samd5x.dtsi:357 */
			status = "disabled";                   /* in zephyr/dts/arm/atmel/samd5x.dtsi:359 */
			#io-channel-cells = < 0x1 >;           /* in zephyr/dts/arm/atmel/samd5x.dtsi:361 */
			prescaler = < 0x4 >;                   /* in zephyr/dts/arm/atmel/samd5x.dtsi:363 */
			calib-offset = < 0x0 >;                /* in zephyr/dts/arm/atmel/samd5x.dtsi:364 */
		};

		/* node '/soc/adc@43002000' defined in zephyr/dts/arm/atmel/samd5x.dtsi:367 */
		adc1: adc@43002000 {
			compatible = "atmel,sam0-adc";         /* in zephyr/dts/arm/atmel/samd5x.dtsi:368 */
			reg = < 0x43002000 0x4a >;             /* in zephyr/dts/arm/atmel/samd5x.dtsi:369 */
			interrupts = < 0x78 0x0 >,
			             < 0x79 0x0 >;             /* in zephyr/dts/arm/atmel/samd5x.dtsi:370 */
			interrupt-names = "overrun",
			                  "resrdy";            /* in zephyr/dts/arm/atmel/samd5x.dtsi:371 */
			clocks = < &gclk 0x29 >,
			         < &mclk 0x20 0x8 >;           /* in zephyr/dts/arm/atmel/samd5x.dtsi:372 */
			clock-names = "GCLK",
			              "MCLK";                  /* in zephyr/dts/arm/atmel/samd5x.dtsi:373 */
			atmel,assigned-clocks = < &gclk 0x2 >; /* in zephyr/dts/arm/atmel/samd5x.dtsi:381 */
			atmel,assigned-clock-names = "GCLK";   /* in zephyr/dts/arm/atmel/samd5x.dtsi:382 */
			status = "disabled";                   /* in zephyr/dts/arm/atmel/samd5x.dtsi:383 */
			#io-channel-cells = < 0x1 >;           /* in zephyr/dts/arm/atmel/samd5x.dtsi:385 */
			prescaler = < 0x4 >;                   /* in zephyr/dts/arm/atmel/samd5x.dtsi:387 */
			calib-offset = < 0xe >;                /* in zephyr/dts/arm/atmel/samd5x.dtsi:388 */
		};

		/* node '/soc/dac@43002400' defined in zephyr/dts/arm/atmel/samd5x.dtsi:391 */
		dac0: dac@43002400 {
			compatible = "atmel,samd5x-dac";       /* in zephyr/dts/arm/atmel/samd5x.dtsi:392 */
			reg = < 0x43002400 0x20 >;             /* in zephyr/dts/arm/atmel/samd5x.dtsi:393 */
			clocks = < &gclk 0x2a >,
			         < &mclk 0x20 0x9 >;           /* in zephyr/dts/arm/atmel/samd5x.dtsi:395 */
			clock-names = "GCLK",
			              "MCLK";                  /* in zephyr/dts/arm/atmel/samd5x.dtsi:396 */
			atmel,assigned-clocks = < &gclk 0x0 >; /* in zephyr/dts/arm/atmel/samd5x.dtsi:397 */
			atmel,assigned-clock-names = "GCLK";   /* in zephyr/dts/arm/atmel/samd5x.dtsi:398 */
			status = "disabled";                   /* in zephyr/dts/arm/atmel/samd5x.dtsi:399 */
			#io-channel-cells = < 0x1 >;           /* in zephyr/dts/arm/atmel/samd5x.dtsi:401 */
		};

		/* node '/soc/tc@40003800' defined in zephyr/dts/arm/atmel/samd5x.dtsi:404 */
		tc0: tc@40003800 {
			compatible = "atmel,sam0-tc32";        /* in zephyr/dts/arm/atmel/samd5x.dtsi:405 */
			reg = < 0x40003800 0x34 >;             /* in zephyr/dts/arm/atmel/samd5x.dtsi:406 */
			interrupts = < 0x6b 0x0 >;             /* in zephyr/dts/arm/atmel/samd5x.dtsi:407 */
			clocks = < &gclk 0x9 >,
			         < &mclk 0x14 0xe >;           /* in zephyr/dts/arm/atmel/samd5x.dtsi:408 */
			clock-names = "GCLK",
			              "MCLK";                  /* in zephyr/dts/arm/atmel/samd5x.dtsi:409 */
			atmel,assigned-clocks = < &gclk 0x0 >; /* in zephyr/dts/arm/atmel/samd5x.dtsi:410 */
			atmel,assigned-clock-names = "GCLK";   /* in zephyr/dts/arm/atmel/samd5x.dtsi:411 */
			status = "disabled";                   /* in zephyr/dts/arm/atmel/samd5x.dtsi:412 */
		};

		/* node '/soc/tc@4101a000' defined in zephyr/dts/arm/atmel/samd5x.dtsi:415 */
		tc2: tc@4101a000 {
			compatible = "atmel,sam0-tc32";        /* in zephyr/dts/arm/atmel/samd5x.dtsi:416 */
			reg = < 0x4101a000 0x34 >;             /* in zephyr/dts/arm/atmel/samd5x.dtsi:417 */
			interrupts = < 0x6d 0x0 >;             /* in zephyr/dts/arm/atmel/samd5x.dtsi:418 */
			clocks = < &gclk 0x1a >,
			         < &mclk 0x18 0xd >;           /* in zephyr/dts/arm/atmel/samd5x.dtsi:419 */
			clock-names = "GCLK",
			              "MCLK";                  /* in zephyr/dts/arm/atmel/samd5x.dtsi:420 */
			atmel,assigned-clocks = < &gclk 0x0 >; /* in zephyr/dts/arm/atmel/samd5x.dtsi:421 */
			atmel,assigned-clock-names = "GCLK";   /* in zephyr/dts/arm/atmel/samd5x.dtsi:422 */
			status = "disabled";                   /* in zephyr/dts/arm/atmel/samd5x.dtsi:423 */
		};

		/* node '/soc/tc@42001400' defined in zephyr/dts/arm/atmel/samd5x.dtsi:426 */
		tc4: tc@42001400 {
			compatible = "atmel,sam0-tc32";        /* in zephyr/dts/arm/atmel/samd5x.dtsi:427 */
			reg = < 0x42001400 0x34 >;             /* in zephyr/dts/arm/atmel/samd5x.dtsi:428 */
			interrupts = < 0x6f 0x0 >;             /* in zephyr/dts/arm/atmel/samd5x.dtsi:429 */
			clocks = < &gclk 0x1e >,
			         < &mclk 0x1c 0x5 >;           /* in zephyr/dts/arm/atmel/samd5x.dtsi:430 */
			clock-names = "GCLK",
			              "MCLK";                  /* in zephyr/dts/arm/atmel/samd5x.dtsi:431 */
			atmel,assigned-clocks = < &gclk 0x0 >; /* in zephyr/dts/arm/atmel/samd5x.dtsi:432 */
			atmel,assigned-clock-names = "GCLK";   /* in zephyr/dts/arm/atmel/samd5x.dtsi:433 */
			status = "disabled";                   /* in zephyr/dts/arm/atmel/samd5x.dtsi:434 */
		};

		/* node '/soc/tc@43001400' defined in zephyr/dts/arm/atmel/samd5x.dtsi:437 */
		tc6: tc@43001400 {
			compatible = "atmel,sam0-tc32";        /* in zephyr/dts/arm/atmel/samd5x.dtsi:438 */
			reg = < 0x43001400 0x34 >;             /* in zephyr/dts/arm/atmel/samd5x.dtsi:439 */
			interrupts = < 0x71 0x0 >;             /* in zephyr/dts/arm/atmel/samd5x.dtsi:440 */
			clocks = < &gclk 0x27 >,
			         < &mclk 0x20 0x5 >;           /* in zephyr/dts/arm/atmel/samd5x.dtsi:441 */
			clock-names = "GCLK",
			              "MCLK";                  /* in zephyr/dts/arm/atmel/samd5x.dtsi:442 */
			atmel,assigned-clocks = < &gclk 0x0 >; /* in zephyr/dts/arm/atmel/samd5x.dtsi:443 */
			atmel,assigned-clock-names = "GCLK";   /* in zephyr/dts/arm/atmel/samd5x.dtsi:444 */
			status = "disabled";                   /* in zephyr/dts/arm/atmel/samd5x.dtsi:445 */
		};

		/* node '/soc/tcc@41016000' defined in zephyr/dts/arm/atmel/samd5x.dtsi:448 */
		tcc0: tcc@41016000 {
			reg = < 0x41016000 0x2000 >;           /* in zephyr/dts/arm/atmel/samd5x.dtsi:450 */
			interrupts = < 0x55 0x0 >,
			             < 0x56 0x0 >,
			             < 0x57 0x0 >,
			             < 0x58 0x0 >,
			             < 0x59 0x0 >,
			             < 0x5a 0x0 >,
			             < 0x5b 0x0 >;             /* in zephyr/dts/arm/atmel/samd5x.dtsi:451 */
			clocks = < &gclk 0x19 >,
			         < &mclk 0x18 0xb >;           /* in zephyr/dts/arm/atmel/samd5x.dtsi:453 */
			clock-names = "GCLK",
			              "MCLK";                  /* in zephyr/dts/arm/atmel/samd5x.dtsi:454 */
			atmel,assigned-clocks = < &gclk 0x0 >; /* in zephyr/dts/arm/atmel/samd5x.dtsi:455 */
			atmel,assigned-clock-names = "GCLK";   /* in zephyr/dts/arm/atmel/samd5x.dtsi:456 */
			channels = < 0x6 >;                    /* in zephyr/dts/arm/atmel/samd5x.dtsi:459 */
			counter-size = < 0x18 >;               /* in zephyr/dts/arm/atmel/samd5x.dtsi:460 */
			status = "okay";                       /* in zephyr/boards/adafruit/itsybitsy_m4_express/adafruit_itsybitsy_m4_express.dts:77 */
			compatible = "atmel,sam0-tcc-pwm";     /* in zephyr/boards/adafruit/itsybitsy_m4_express/adafruit_itsybitsy_m4_express.dts:78 */
			prescaler = < 0x8 >;                   /* in zephyr/boards/adafruit/itsybitsy_m4_express/adafruit_itsybitsy_m4_express.dts:79 */
			#pwm-cells = < 0x2 >;                  /* in zephyr/boards/adafruit/itsybitsy_m4_express/adafruit_itsybitsy_m4_express.dts:80 */
			pinctrl-0 = < &pwm0_default >;         /* in zephyr/boards/adafruit/itsybitsy_m4_express/adafruit_itsybitsy_m4_express.dts:82 */
			pinctrl-names = "default";             /* in zephyr/boards/adafruit/itsybitsy_m4_express/adafruit_itsybitsy_m4_express.dts:83 */
			phandle = < 0xa >;                     /* in zephyr/boards/adafruit/itsybitsy_m4_express/adafruit_itsybitsy_m4_express.dts:43 */
		};

		/* node '/soc/tcc@41018000' defined in zephyr/dts/arm/atmel/samd5x.dtsi:463 */
		tcc1: tcc@41018000 {
			compatible = "atmel,sam0-tcc";         /* in zephyr/dts/arm/atmel/samd5x.dtsi:464 */
			reg = < 0x41018000 0x2000 >;           /* in zephyr/dts/arm/atmel/samd5x.dtsi:465 */
			interrupts = < 0x5c 0x0 >,
			             < 0x5d 0x0 >,
			             < 0x5e 0x0 >,
			             < 0x5f 0x0 >,
			             < 0x60 0x0 >;             /* in zephyr/dts/arm/atmel/samd5x.dtsi:466 */
			clocks = < &gclk 0x19 >,
			         < &mclk 0x18 0xc >;           /* in zephyr/dts/arm/atmel/samd5x.dtsi:467 */
			clock-names = "GCLK",
			              "MCLK";                  /* in zephyr/dts/arm/atmel/samd5x.dtsi:468 */
			atmel,assigned-clocks = < &gclk 0x0 >; /* in zephyr/dts/arm/atmel/samd5x.dtsi:469 */
			atmel,assigned-clock-names = "GCLK";   /* in zephyr/dts/arm/atmel/samd5x.dtsi:470 */
			status = "disabled";                   /* in zephyr/dts/arm/atmel/samd5x.dtsi:471 */
			channels = < 0x4 >;                    /* in zephyr/dts/arm/atmel/samd5x.dtsi:473 */
			counter-size = < 0x18 >;               /* in zephyr/dts/arm/atmel/samd5x.dtsi:474 */
		};

		/* node '/soc/tcc@42000c00' defined in zephyr/dts/arm/atmel/samd5x.dtsi:477 */
		tcc2: tcc@42000c00 {
			compatible = "atmel,sam0-tcc";         /* in zephyr/dts/arm/atmel/samd5x.dtsi:478 */
			reg = < 0x42000c00 0x400 >;            /* in zephyr/dts/arm/atmel/samd5x.dtsi:479 */
			interrupts = < 0x61 0x0 >,
			             < 0x62 0x0 >,
			             < 0x63 0x0 >,
			             < 0x64 0x0 >;             /* in zephyr/dts/arm/atmel/samd5x.dtsi:480 */
			clocks = < &gclk 0x1d >,
			         < &mclk 0x1c 0x3 >;           /* in zephyr/dts/arm/atmel/samd5x.dtsi:481 */
			clock-names = "GCLK",
			              "MCLK";                  /* in zephyr/dts/arm/atmel/samd5x.dtsi:482 */
			atmel,assigned-clocks = < &gclk 0x0 >; /* in zephyr/dts/arm/atmel/samd5x.dtsi:483 */
			atmel,assigned-clock-names = "GCLK";   /* in zephyr/dts/arm/atmel/samd5x.dtsi:484 */
			status = "disabled";                   /* in zephyr/dts/arm/atmel/samd5x.dtsi:485 */
			channels = < 0x3 >;                    /* in zephyr/dts/arm/atmel/samd5x.dtsi:487 */
			counter-size = < 0x10 >;               /* in zephyr/dts/arm/atmel/samd5x.dtsi:488 */
		};

		/* node '/soc/tcc@42001000' defined in zephyr/dts/arm/atmel/samd5x.dtsi:491 */
		tcc3: tcc@42001000 {
			compatible = "atmel,sam0-tcc";         /* in zephyr/dts/arm/atmel/samd5x.dtsi:492 */
			reg = < 0x42001000 0x400 >;            /* in zephyr/dts/arm/atmel/samd5x.dtsi:493 */
			interrupts = < 0x65 0x0 >,
			             < 0x66 0x0 >,
			             < 0x67 0x0 >;             /* in zephyr/dts/arm/atmel/samd5x.dtsi:494 */
			clocks = < &gclk 0x1d >,
			         < &mclk 0x1c 0x4 >;           /* in zephyr/dts/arm/atmel/samd5x.dtsi:495 */
			clock-names = "GCLK",
			              "MCLK";                  /* in zephyr/dts/arm/atmel/samd5x.dtsi:496 */
			atmel,assigned-clocks = < &gclk 0x0 >; /* in zephyr/dts/arm/atmel/samd5x.dtsi:497 */
			atmel,assigned-clock-names = "GCLK";   /* in zephyr/dts/arm/atmel/samd5x.dtsi:498 */
			status = "disabled";                   /* in zephyr/dts/arm/atmel/samd5x.dtsi:499 */
			channels = < 0x2 >;                    /* in zephyr/dts/arm/atmel/samd5x.dtsi:501 */
			counter-size = < 0x10 >;               /* in zephyr/dts/arm/atmel/samd5x.dtsi:502 */
		};

		/* node '/soc/tcc@43001000' defined in zephyr/dts/arm/atmel/samd5x.dtsi:505 */
		tcc4: tcc@43001000 {
			compatible = "atmel,sam0-tcc";         /* in zephyr/dts/arm/atmel/samd5x.dtsi:506 */
			reg = < 0x43001000 0x400 >;            /* in zephyr/dts/arm/atmel/samd5x.dtsi:507 */
			interrupts = < 0x68 0x0 >,
			             < 0x69 0x0 >,
			             < 0x6a 0x0 >;             /* in zephyr/dts/arm/atmel/samd5x.dtsi:508 */
			clocks = < &gclk 0x26 >,
			         < &mclk 0x20 0x4 >;           /* in zephyr/dts/arm/atmel/samd5x.dtsi:509 */
			clock-names = "GCLK",
			              "MCLK";                  /* in zephyr/dts/arm/atmel/samd5x.dtsi:510 */
			atmel,assigned-clocks = < &gclk 0x0 >; /* in zephyr/dts/arm/atmel/samd5x.dtsi:511 */
			atmel,assigned-clock-names = "GCLK";   /* in zephyr/dts/arm/atmel/samd5x.dtsi:512 */
			status = "disabled";                   /* in zephyr/dts/arm/atmel/samd5x.dtsi:513 */
			channels = < 0x2 >;                    /* in zephyr/dts/arm/atmel/samd5x.dtsi:515 */
			counter-size = < 0x10 >;               /* in zephyr/dts/arm/atmel/samd5x.dtsi:516 */
		};
	};

	/* node '/cpus' defined in zephyr/dts/arm/atmel/samd5x.dtsi:55 */
	cpus {
		#address-cells = < 0x1 >; /* in zephyr/dts/arm/atmel/samd5x.dtsi:56 */
		#size-cells = < 0x0 >;    /* in zephyr/dts/arm/atmel/samd5x.dtsi:57 */

		/* node '/cpus/cpu@0' defined in zephyr/dts/arm/atmel/samd5x.dtsi:59 */
		cpu0: cpu@0 {
			compatible = "arm,cortex-m4f";   /* in zephyr/dts/arm/atmel/samd5x.dtsi:60 */
			reg = < 0x0 >;                   /* in zephyr/dts/arm/atmel/samd5x.dtsi:61 */
			#address-cells = < 0x1 >;        /* in zephyr/dts/arm/atmel/samd5x.dtsi:63 */
			#size-cells = < 0x1 >;           /* in zephyr/dts/arm/atmel/samd5x.dtsi:64 */
			device_type = "cpu";             /* in zephyr/dts/arm/atmel/samd5x.dtsi:66 */
			clock-frequency = < 0x7270e00 >; /* in zephyr/boards/adafruit/itsybitsy_m4_express/adafruit_itsybitsy_m4_express.dts:49 */

			/* node '/cpus/cpu@0/mpu@e000ed90' defined in zephyr/dts/arm/atmel/samd5x.dtsi:68 */
			mpu: mpu@e000ed90 {
				compatible = "arm,armv7m-mpu"; /* in zephyr/dts/arm/atmel/samd5x.dtsi:69 */
				reg = < 0xe000ed90 0x40 >;     /* in zephyr/dts/arm/atmel/samd5x.dtsi:70 */
			};
		};
	};

	/* node '/leds' defined in zephyr/boards/adafruit/itsybitsy_m4_express/adafruit_itsybitsy_m4_express.dts:30 */
	leds {
		compatible = "gpio-leds"; /* in zephyr/boards/adafruit/itsybitsy_m4_express/adafruit_itsybitsy_m4_express.dts:31 */

		/* node '/leds/led_0' defined in zephyr/boards/adafruit/itsybitsy_m4_express/adafruit_itsybitsy_m4_express.dts:33 */
		led0: led_0 {
			gpios = < &porta 0x16 0x0 >; /* in zephyr/boards/adafruit/itsybitsy_m4_express/adafruit_itsybitsy_m4_express.dts:34 */
			label = "LED";               /* in zephyr/boards/adafruit/itsybitsy_m4_express/adafruit_itsybitsy_m4_express.dts:35 */
		};
	};

	/* node '/pwmleds' defined in zephyr/boards/adafruit/itsybitsy_m4_express/adafruit_itsybitsy_m4_express.dts:39 */
	pwmleds {
		compatible = "pwm-leds"; /* in zephyr/boards/adafruit/itsybitsy_m4_express/adafruit_itsybitsy_m4_express.dts:40 */

		/* node '/pwmleds/pwm_led_0' defined in zephyr/boards/adafruit/itsybitsy_m4_express/adafruit_itsybitsy_m4_express.dts:42 */
		pwm_led0: pwm_led_0 {
			pwms = < &tcc0 0x2 0x1312d00 >; /* in zephyr/boards/adafruit/itsybitsy_m4_express/adafruit_itsybitsy_m4_express.dts:43 */
		};
	};
};
